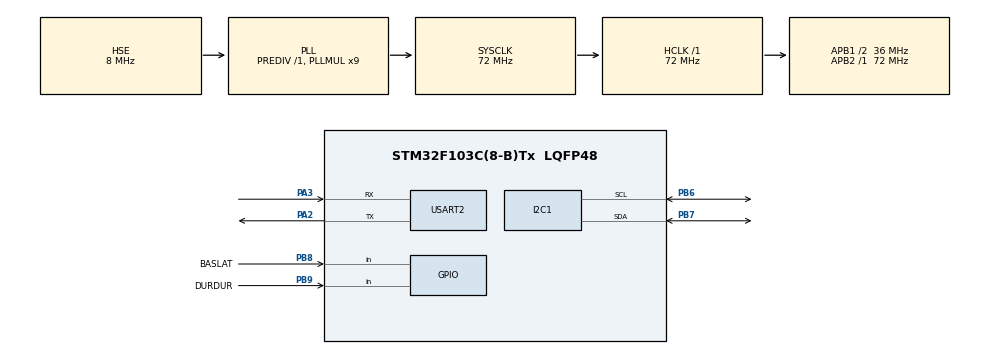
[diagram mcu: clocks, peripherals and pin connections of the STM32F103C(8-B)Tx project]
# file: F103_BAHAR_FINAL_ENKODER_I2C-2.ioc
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I2C1.I2C_Mode=I2C_Fast
Mcu.Family=STM32F1
Mcu.Name=STM32F103C(8-B)Tx
Mcu.Package=LQFP48
NVIC.I2C1_ER_IRQn=true\:0\:0\:false\:false\:true\:true\:true
NVIC.I2C1_EV_IRQn=true\:0\:0\:false\:false\:true\:true\:true
NVIC.PriorityGroup=NVIC_PRIORITYGROUP_4
NVIC.USART2_IRQn=true\:0\:0\:false\:false\:true\:true\:true
PA13.Mode=Serial_Wire
PA13.Signal=SYS_JTMS-SWDIO
PA14.Mode=Serial_Wire
PA14.Signal=SYS_JTCK-SWCLK
PA2.Mode=Asynchronous
PA2.Signal=USART2_TX
PA3.Mode=Asynchronous
PA3.Signal=USART2_RX
PB6.Mode=I2C
PB6.Signal=I2C1_SCL
PB7.Mode=I2C
PB7.Signal=I2C1_SDA
PB8.GPIO_Label=BASLAT
PB8.Signal=GPIO_Input
PB9.GPIO_Label=DURDUR
PB9.Signal=GPIO_Input
PD0-OSC_IN.Mode=HSE-External-Oscillator
PD0-OSC_IN.Signal=RCC_OSC_IN
PD1-OSC_OUT.Mode=HSE-External-Oscillator
PD1-OSC_OUT.Signal=RCC_OSC_OUT
ProjectManager.HeapSize=0x200
ProjectManager.StackSize=0x400
ProjectManager.TargetToolchain=SW4STM32
RCC.AHBFreq_Value=72000000
RCC.APB1CLKDivider=RCC_HCLK_DIV2
RCC.APB1Freq_Value=36000000
RCC.APB1TimFreq_Value=72000000
RCC.APB2Freq_Value=72000000
RCC.APB2TimFreq_Value=72000000
RCC.HCLKFreq_Value=72000000
RCC.PLLMUL=RCC_PLL_MUL9
RCC.PLLSourceVirtual=RCC_PLLSOURCE_HSE
RCC.SYSCLKFreq_VALUE=72000000
RCC.SYSCLKSource=RCC_SYSCLKSOURCE_PLLCLK
RCC.USBFreq_Value=72000000
USART2.VirtualMode=VM_ASYNC
board=custom

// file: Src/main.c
/* USER CODE BEGIN Header */
/**
  ******************************************************************************
  * @file           : main.c
  * @brief          : Main program body
  ******************************************************************************
  * @attention
  *
  * <h2><center>&copy; Copyright (c) 2019 STMicroelectronics.
  * All rights reserved.</center></h2>
  *
  * This software component is licensed by ST under BSD 3-Clause license,
  * the "License"; You may not use this file except in compliance with the
  * License. You may obtain a copy of the License at:
  *                        opensource.org/licenses/BSD-3-Clause
  *
  ******************************************************************************
  */
/* USER CODE END Header */

#include "main.h"

I2C_HandleTypeDef hi2c1;

UART_HandleTypeDef huart2;

void SystemClock_Config(void);
static void MX_GPIO_Init(void);
static void MX_USART2_UART_Init(void);
static void MX_I2C1_Init(void);

/* USER CODE BEGIN 0 */
uint8_t aRxBuffer[5];
/* USER CODE END 0 */

int main(void)
{

  /* MCU Configuration--------------------------------------------------------*/

  /* Reset of all peripherals, Initializes the Flash interface and the Systick. */
  HAL_Init();

  /* Configure the system clock */
  SystemClock_Config();

  /* Initialize all configured peripherals */
  MX_GPIO_Init();
  MX_USART2_UART_Init();
  MX_I2C1_Init();

  /* Infinite loop */
  /* USER CODE BEGIN WHILE */
  while (1)
  {
	  if(HAL_GPIO_ReadPin(GPIOB, GPIO_PIN_8)== 1)
	  {
		  if(HAL_I2C_Master_Transmit(&hi2c1,(uint16_t)0x30F, (uint8_t*)"B",1,100)==HAL_OK){
			  Error_Handler();
		  }
	  }
	  if(HAL_GPIO_ReadPin(GPIOB, GPIO_PIN_9)== 1)
	  {
		  if(HAL_I2C_Master_Transmit(&hi2c1,(uint16_t)0x30F, (uint8_t*)"D",1,100)==HAL_OK){
			  Error_Handler();
		  }
	  }
  }
}

void HAL_I2C_SlaveRxCpltCallback(I2C_HandleTypeDef *hi2c)
{
	if(HAL_I2C_Master_Receive(&hi2c1, (uint8_t *)aRxBuffer, 5, 100)!= HAL_OK){
		Error_Handler();
	}

	if(HAL_UART_Transmit(&huart2, (uint8_t *)aRxBuffer,5,100)!= HAL_OK){
		Error_Handler();
	}
}

void SystemClock_Config(void)
{
  RCC_OscInitTypeDef RCC_OscInitStruct = {0};
  RCC_ClkInitTypeDef RCC_ClkInitStruct = {0};

  /** Initializes the CPU, AHB and APB busses clocks
  */
  RCC_OscInitStruct.OscillatorType = RCC_OSCILLATORTYPE_HSE;
  RCC_OscInitStruct.HSEState = RCC_HSE_ON;
  RCC_OscInitStruct.HSEPredivValue = RCC_HSE_PREDIV_DIV1;
  RCC_OscInitStruct.HSIState = RCC_HSI_ON;
  RCC_OscInitStruct.PLL.PLLState = RCC_PLL_ON;
  RCC_OscInitStruct.PLL.PLLSource = RCC_PLLSOURCE_HSE;
  RCC_OscInitStruct.PLL.PLLMUL = RCC_PLL_MUL9;
  if (HAL_RCC_OscConfig(&RCC_OscInitStruct) != HAL_OK)
  {
    Error_Handler();
  }
  /** Initializes the CPU, AHB and APB busses clocks
  */
  RCC_ClkInitStruct.ClockType = RCC_CLOCKTYPE_HCLK|RCC_CLOCKTYPE_SYSCLK
                              |RCC_CLOCKTYPE_PCLK1|RCC_CLOCKTYPE_PCLK2;
  RCC_ClkInitStruct.SYSCLKSource = RCC_SYSCLKSOURCE_PLLCLK;
  RCC_ClkInitStruct.AHBCLKDivider = RCC_SYSCLK_DIV1;
  RCC_ClkInitStruct.APB1CLKDivider = RCC_HCLK_DIV2;
  RCC_ClkInitStruct.APB2CLKDivider = RCC_HCLK_DIV1;

  if (HAL_RCC_ClockConfig(&RCC_ClkInitStruct, FLASH_LATENCY_2) != HAL_OK)
  {
    Error_Handler();
  }
}

static void MX_I2C1_Init(void)
{

  hi2c1.Instance = I2C1;
  hi2c1.Init.ClockSpeed = 400000;
  hi2c1.Init.DutyCycle = I2C_DUTYCYCLE_2;
  hi2c1.Init.OwnAddress1 = 0;
  hi2c1.Init.AddressingMode = I2C_ADDRESSINGMODE_7BIT;
  hi2c1.Init.DualAddressMode = I2C_DUALADDRESS_DISABLE;
  hi2c1.Init.OwnAddress2 = 0;
  hi2c1.Init.GeneralCallMode = I2C_GENERALCALL_DISABLE;
  hi2c1.Init.NoStretchMode = I2C_NOSTRETCH_DISABLE;
  if (HAL_I2C_Init(&hi2c1) != HAL_OK)
  {
    Error_Handler();
  }

}

static void MX_USART2_UART_Init(void)
{

  huart2.Instance = USART2;
  huart2.Init.BaudRate = 115200;
  huart2.Init.WordLength = UART_WORDLENGTH_8B;
  huart2.Init.StopBits = UART_STOPBITS_1;
  huart2.Init.Parity = UART_PARITY_NONE;
  huart2.Init.Mode = UART_MODE_TX_RX;
  huart2.Init.HwFlowCtl = UART_HWCONTROL_NONE;
  huart2.Init.OverSampling = UART_OVERSAMPLING_16;
  if (HAL_UART_Init(&huart2) != HAL_OK)
  {
    Error_Handler();
  }

}

static void MX_GPIO_Init(void)
{
  GPIO_InitTypeDef GPIO_InitStruct = {0};

  /* GPIO Ports Clock Enable */
  __HAL_RCC_GPIOD_CLK_ENABLE();
  __HAL_RCC_GPIOA_CLK_ENABLE();
  __HAL_RCC_GPIOB_CLK_ENABLE();

  /*Configure GPIO pins : BASLAT_Pin DURDUR_Pin */
  GPIO_InitStruct.Pin = BASLAT_Pin|DURDUR_Pin;
  GPIO_InitStruct.Mode = GPIO_MODE_INPUT;
  GPIO_InitStruct.Pull = GPIO_NOPULL;
  HAL_GPIO_Init(GPIOB, &GPIO_InitStruct);

}

void Error_Handler(void)
{
}

/************************ (C) COPYRIGHT STMicroelectronics *****END OF FILE****/
